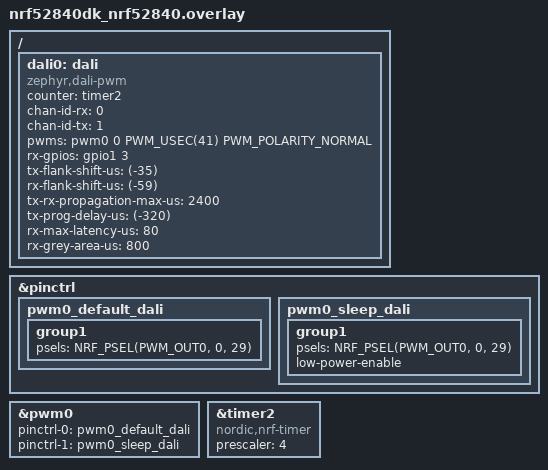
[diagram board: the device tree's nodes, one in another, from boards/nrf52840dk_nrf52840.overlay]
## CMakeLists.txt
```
cmake_minimum_required(VERSION 3.28.0)
find_package(Zephyr REQUIRED HINTS $ENV{ZEPHYR_BASE})
project(dali_app LANGUAGES C)
target_sources(app PRIVATE src/main.c)
```

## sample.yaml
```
sample:
  description: Dali Zephyr driver application
  name: dali-zephyr
common:
  build_only: true
  integration_platforms:
    - nucleo_f091rc
    - nrf52840dk/nrf52840
tests:
  app.default: {}
  app.debug:
    extra_overlay_confs:
      - debug.conf
```

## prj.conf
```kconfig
CONFIG_DALI=y

CONFIG_LOG=y
CONFIG_LOG_DEFAULT_LEVEL=3
```

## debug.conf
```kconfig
# manage output stream
CONFIG_USE_SEGGER_RTT=y

# logging
CONFIG_LOG=y
CONFIG_LOG_MODE_IMMEDIATE=y
CONFIG_LOG_PRINTK=y
CONFIG_LOG_BACKEND_UART=n
CONFIG_LOG_BACKEND_RTT=y
CONFIG_LOG_BACKEND_SHOW_COLOR=n
CONFIG_LOG_BACKEND_RTT_MODE_DROP=y
CONFIG_DALI_LOW_LEVEL_LOG_LEVEL_DBG=y

# debugger support
CONFIG_DEBUG_OPTIMIZATIONS=y
CONFIG_THREAD_MONITOR=y
CONFIG_ASSERT=y
CONFIG_THREAD_NAME=y
CONFIG_THREAD_ANALYZER=y
```

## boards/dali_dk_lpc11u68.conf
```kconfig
CONFIG_EEPROM=y
CONFIG_CRC=y
```

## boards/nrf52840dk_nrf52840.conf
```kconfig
CONFIG_GPIO=y
CONFIG_COUNTER=y
CONFIG_ZERO_LATENCY_IRQS=y

CONFIG_FLASH=y
CONFIG_NVS=y
CONFIG_NVS_LOG_LEVEL_DBG=y
```

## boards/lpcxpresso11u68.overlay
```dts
/*
 * Copyright 2025 by Sven Hädrich <sven.haedrich@sevenlab.de>
 * SPDX-License-Identifier: Apache-2.0
 *
 * use the DALI-interface via DALI 2 Click-(MIKROE-1581) adapter-board
 * connect DALI Tx to port 0.11
 * connect DALI Rx to port 0.12
 */

/ {
	dali0: dali {
		compatible = "nxp,dali-lpc11u6x";
		status = "okay";
		interrupt-parent = <&nvic>;
		#interrupt-cells = <2>;
		interrupts = <18 1>, <19 1>;
		tx-rise-fall-delta-us = <(-44)>;
		rx-rise-fall-delta-us = <(-48)>;
		tx-rx-propagation-min-us = <80>;
		tx-rx-propagation-max-us = <125>;
	};
};
```

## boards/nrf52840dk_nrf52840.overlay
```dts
/*
 * Copyright 2025 by Markus Becker
 * SPDX-License-Identifier: Apache-2.0
 *
 * add DALI 2 Click (MIKROE-2672)
 * via Arduino UNO click shield (MIKROE-1581)
 * to nRF52840 DK (pca10056)
 * DALI 2 Click
 *   DALI TX 2
 *   DALI RX 15
 * Arduino UNO click shield (slot 1)
 *   DALI TX 2  > A3
 *   DALI RX 15 > D2
 * nRF52840 DK:
 *   DALI TX A3 > P0.29
 *   DALI RX D2 > P1.03
 */

/ {
	dali0: dali {
		compatible = "zephyr,dali-pwm";
		status = "okay";
		counter = <&timer2>;
		chan-id-rx = 0;
		chan-id-tx = 1;
		pwms = <&pwm0 0 PWM_USEC(41) PWM_POLARITY_NORMAL>;
		rx-gpios = <&gpio1 3 GPIO_ACTIVE_HIGH>; // D2
		tx-flank-shift-us = <(-35)>;
		rx-flank-shift-us = <(-59)>;
		tx-rx-propagation-max-us = <2400>;
		tx-prog-delay-us = <(-320)>;
		rx-max-latency-us = <80>;
		rx-grey-area-us = <800>;
	};
};

&pinctrl {
	pwm0_default_dali: pwm0_default_dali {
		group1 {
			psels = <NRF_PSEL(PWM_OUT0, 0, 29)>; // A3
		};
	};

	pwm0_sleep_dali: pwm0_sleep_dali {
		group1 {
			psels = <NRF_PSEL(PWM_OUT0, 0, 29)>; // A3
			low-power-enable;
		};
	};
};

&pwm0 {
	status = "okay";
	pinctrl-0 = <&pwm0_default_dali>;
	pinctrl-1 = <&pwm0_sleep_dali>;
	pinctrl-names = "default", "sleep";
};

&timer2 {
	compatible = "nordic,nrf-timer";
	status = "okay";
	prescaler = <4>;
};
```

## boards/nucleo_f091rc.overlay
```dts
/*
 * Copyright 2026 by Sven Hädrich <sven.haedrich@sevenlab.de>
 * SPDX-License-Identifier: Apache-2.0
 *
 * add DALI 2 Click (MIKROE-2672)
 * via Arduino UNO click shield (MIKROE-1581)
 * to STM32 NUCLEO F091RC
 * DALI 2 Click
 *   DALI TX 2
 *   DALI RX 15
 * Arduino UNO click shield (slot 1)
 *   DALI TX 2 > A3
 *   DALI RX 15 > D2
 * STM32F091
 *   DALI TX A3 > PB_0
 *   DALI RX D2 > PA_10
 */

&mikroe_dali2_click {
	counter = <&counter2>;
	pwms = <&pwm3 3 PWM_USEC(41) PWM_POLARITY_NORMAL>;
	tx-rx-propagation-max-us = <2400>;
	tx-prog-delay-us = <(-200)>;
	rx-max-latency-us = <80>;
	rx-grey-area-us = <800>;
};

&timers2 {
	interrupts = <15 1>;
	// set timebase to 1us/1MHz
	st,prescaler = <47>;
	status = "okay";

	counter2: counter {
		compatible = "st,stm32-counter";
		status = "okay";
	};
};

&timers3 {
	// set timebase to 1us/1MHz
	st,prescaler = <47>;
	status = "okay";

	pwm3: pwm {
		pinctrl-0 = <&tim3_ch3_pb0>; // microbus header 1
		pinctrl-names = "default";
		status = "okay";
	};
};
```

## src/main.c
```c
/*
 * Copyright (c) 2025 by Sven Hädrich <sven.haedrich@sevenlab.de>
 * SPDX-License-Identifier: Apache-2.0
 */

#include <stdio.h>

#include <zephyr/kernel.h>
#include <zephyr/drivers/led.h>
#include <zephyr/drivers/dali.h>

#include <zephyr/logging/log.h>
LOG_MODULE_REGISTER(main);

#define DALI_NODE DT_ALIAS(dali)

int main(void)
{
	const struct device *dali_dev = DEVICE_DT_GET(DALI_NODE);
	int ret;

	LOG_INF("DALI Blinky");
	LOG_INF("Target board: %s", CONFIG_BOARD_TARGET);

	if (!device_is_ready(dali_dev)) {
		LOG_ERR("failed to get DALI device.");
		return 0;
	}

	/* DALI frame that commands max brightness */
	/* see iec 62386-102 for full details */
	/* data low byte - opcode byte : 0x05 - RECALL MAX LEVEL */
	/* data high byte - address byte : 0xFF - broadcast */
	const struct dali_frame frame_recall_max = (struct dali_frame){
		.event_type = DALI_FRAME_GEAR,
		.data = 0xff05,
	};
	/* DALI frame that commands off */
	/* see iec 62386-102 for full details */
	/* data low byte - opcode byte : 0x00 - OFF */
	/* data high byte - address byte : 0xFF - broadcast */
	const struct dali_frame frame_off = (struct dali_frame){
		.event_type = DALI_FRAME_GEAR,
		.data = 0xff00,
	};

	/* transmit on / off DALI frames */
	for (;;) {
		ret = dali_transmit(dali_dev, &frame_recall_max, NULL, NULL);
		if (ret < 0) {
			LOG_ERR("failed to transmit recall max with error code %d", ret);
			return -1;
		}
		k_sleep(K_MSEC(2000));
		ret = dali_transmit(dali_dev, &frame_off, NULL, NULL);
		if (ret < 0) {
			LOG_ERR("failed to transmit off with error code %d", ret);
			return -1;
		}
		k_sleep(K_MSEC(2000));
	}
	return 0;
}
```
